# NAVSS0_PVU_0_PVU0_SRC_TOG_CFG register map
Vendor: Texas Instruments
Peripheral module from a debugger description file (folder J7_AHP).
Registers are 32-bit, read-only, reset 0x0 unless marked. A register's access mark holds for its fields unless they carry their own. Offsets are as the file gives them; lines under a group give offsets from that group; [hi:lo] are bit positions; {n}, {i} and the like mark numbered series; 'fields as' and 'values as' point back to an identical list; <NAME> marks a mode.

## NAVSS0_PVU_0_PVU0_SRC_TOG_CFG
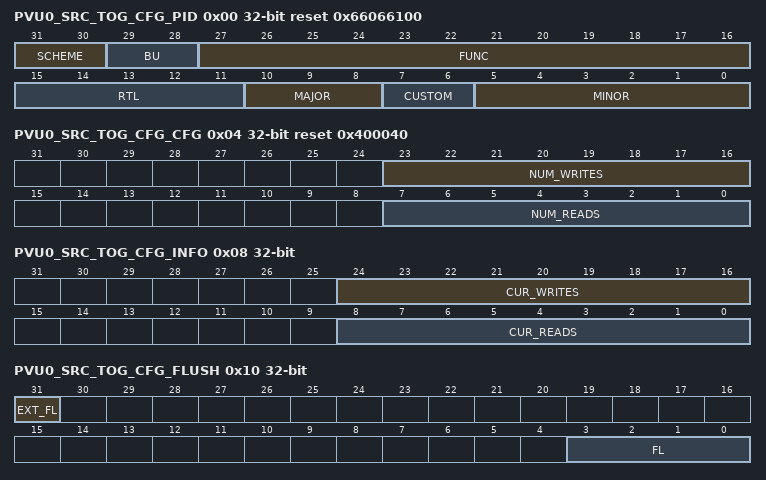
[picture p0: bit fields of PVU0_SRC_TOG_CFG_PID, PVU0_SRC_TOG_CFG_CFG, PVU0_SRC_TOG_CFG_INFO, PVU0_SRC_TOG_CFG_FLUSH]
0x00 PVU0_SRC_TOG_CFG_PID reset 0x66066100
  [31:30] SCHEME — PID register scheme
  [29:28] BU — Business Unit: 10 = Processors
  [27:16] FUNC — Module ID
  [15:11] RTL — RTL revision. Will vary depending on release.
  [10:8] MAJOR — Major revision
  [7:6] CUSTOM
  [5:0] MINOR — Minor revision
0x04 PVU0_SRC_TOG_CFG_CFG reset 0x400040
  [23:16] NUM_WRITES — Total Number of slots in the write scoreboard
  [7:0] NUM_READS — Total Number of slots in the read scoreboard
0x08 PVU0_SRC_TOG_CFG_INFO
  [24:16] CUR_WRITES — Total Number of slots in the write scoreboard
  [8:0] CUR_READS — Total Number of slots in the read scoreboard
0x0C PVU0_SRC_TOG_CFG_ENABLE rw
  [3:0] EN — Enable. 0 - Disabled, All other values - Enabled.
0x10 PVU0_SRC_TOG_CFG_FLUSH access per field
  [31] EXT_FL ro — External Flush Value
  [3:0] FL rw — Enable. 4'b1111 - Flush, All other values - Normal.
0x14 PVU0_SRC_TOG_CFG_TIMEOUT rw reset 0x3FFFFFFF
  [29:0] TO — The number of cycles in each eon.
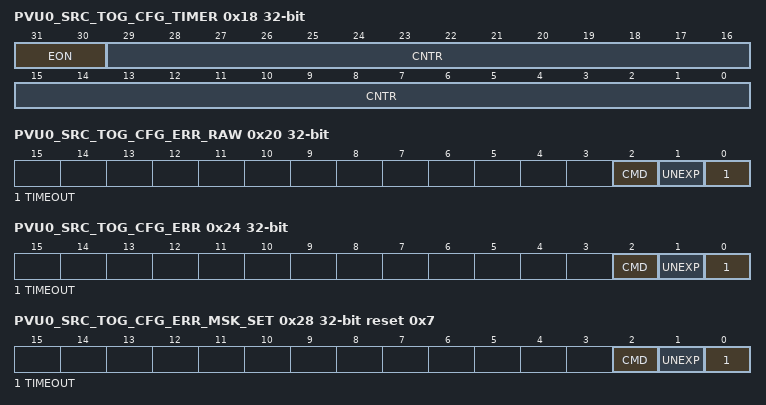
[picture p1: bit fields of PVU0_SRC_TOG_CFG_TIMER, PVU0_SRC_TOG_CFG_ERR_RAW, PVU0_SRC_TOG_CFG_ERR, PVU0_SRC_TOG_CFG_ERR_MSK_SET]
0x18 PVU0_SRC_TOG_CFG_TIMER access not given
  [31:30] EON ro — Current eon
  [29:0] CNTR — Current value of the free-running timer (access R/WTC)
0x20 PVU0_SRC_TOG_CFG_ERR_RAW access not given
  [2] CMD — Raw Command Error Interrupt (access R/W1TS)
  [1] UNEXP — Raw Unexpected Error Interrupt (access R/W1TS)
  [0] TIMEOUT — Raw Timeout Error Interrupt (access R/W1TS)
0x24 PVU0_SRC_TOG_CFG_ERR access not given
  [2] CMD — Masked Command Error Interrupt (access R/W1TC)
  [1] UNEXP — Masked Unexpected Error Interrupt (access R/W1TC)
  [0] TIMEOUT — Masked Timeout Error Interrupt (access R/W1TC)
0x28 PVU0_SRC_TOG_CFG_ERR_MSK_SET access not given reset 0x7
  [2] CMD — Raw Command Error Interrupt Mask Set (access R/W1TS)
  [1] UNEXP — Raw Unexpected Error Interrupt Mask Set (access R/W1TS)
  [0] TIMEOUT — Raw Timeout Error Interrupt Mask Set (access R/W1TS)
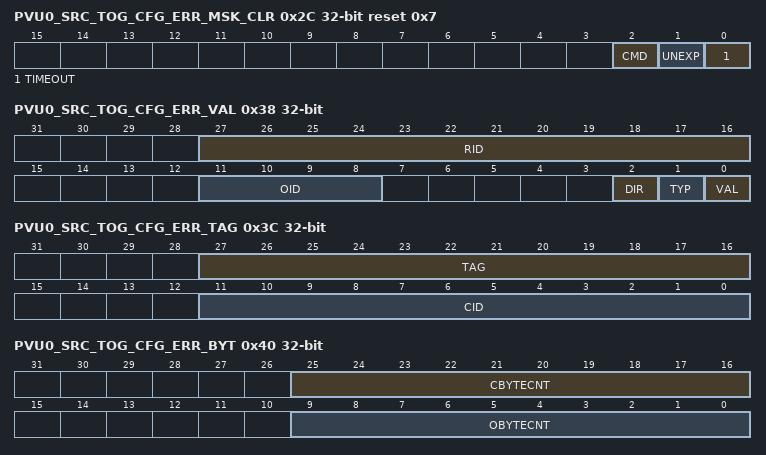
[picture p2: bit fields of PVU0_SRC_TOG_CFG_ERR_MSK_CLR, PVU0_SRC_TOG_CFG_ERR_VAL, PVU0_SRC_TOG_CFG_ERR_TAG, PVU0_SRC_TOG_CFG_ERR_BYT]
0x2C PVU0_SRC_TOG_CFG_ERR_MSK_CLR access not given reset 0x7
  [2] CMD — Raw Command Error Interrupt Mask Clear (access R/W1TC)
  [1] UNEXP — Raw Unexpected Error Interrupt Mask Clear (access R/W1TC)
  [0] TIMEOUT — Raw Timeout Error Interrupt Mask Clear (access R/W1TC)
0x30 PVU0_SRC_TOG_CFG_ERR_TM_INFO access not given
  [1:0] CNT — Timeout Interrupt Count (access R/WTD)
0x34 PVU0_SRC_TOG_CFG_ERR_UN_INFO access not given
  [1:0] CNT — Unexpected Interrupt Count (access R/WTD)
0x38 PVU0_SRC_TOG_CFG_ERR_VAL
  [27:16] RID — Route ID Indicator
  [11:8] OID — Order ID Indicator
  [2] DIR — Direction Indicator
  [1] TYP — Type Indicator
  [0] VAL — Valid Indicator
0x3C PVU0_SRC_TOG_CFG_ERR_TAG
  [27:16] TAG — Command Tag Indicator
  [11:0] CID — Command ID Indicator
0x40 PVU0_SRC_TOG_CFG_ERR_BYT
  [25:16] CBYTECNT — Current Bytecnt
  [9:0] OBYTECNT — Original Bytecnt
0x44 PVU0_SRC_TOG_CFG_ERR_ADDR_U
  [31:0] ADDR — Upper bits of the Address
0x48 PVU0_SRC_TOG_CFG_ERR_ADDR_L
  [31:0] ADDR — Lower bits of the Address
